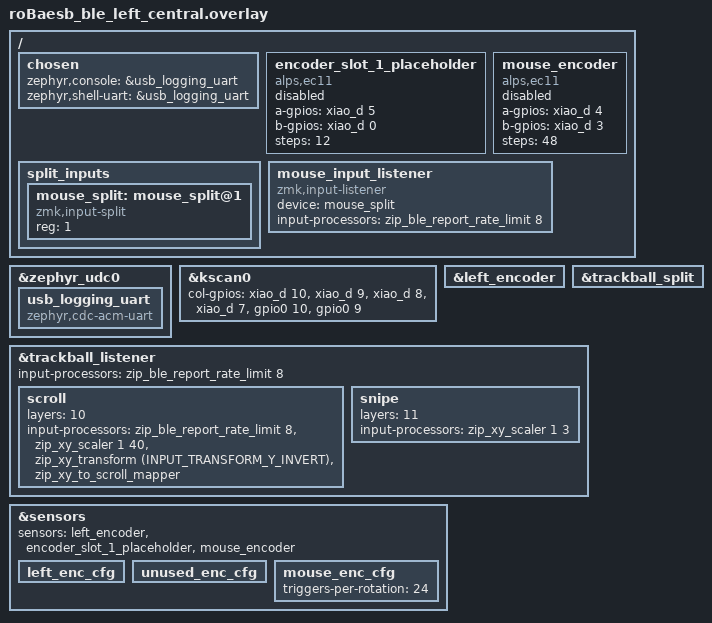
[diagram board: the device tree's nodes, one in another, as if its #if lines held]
/*
 * Left half of roBa acting as ESB central + BLE host.
 *
 * Peripherals:
 *   roBaesb_right  (ID=2, reg=0) — right keys + PMW3610 trackball
 *   lariska_esb    (ID=3, reg=1) — PAW3395 mouse + 5 buttons
 *
 * Both peripherals must use roBaesb_addr.dtsi (the standard address set).
 */

#include "../roBa/roBa.dtsi"
#ifdef ZMK_ESB_ADDR_B
#include "roBaesb_addr_b.dtsi"
#else
#include "roBaesb_addr.dtsi"
#endif
#ifdef ZMK_ESB_MOUSE
#include "roBaesb_lariska_transform.dtsi"
#endif

#include <input/processors/xyz.dtsi>
#include <input/processors/report_rate_limit.dtsi>

/ {
    chosen {
        zephyr,console = &usb_logging_uart;
        zephyr,shell-uart = &usb_logging_uart;
    };

#ifdef ZMK_ESB_MOUSE
    /* Disabled EC11 at sensors[2] - positional placeholder so lariska's encoder
     * (which fires at peripheral sensor index 2) maps to sensor-bindings[2].
     * encoder_slot_1_placeholder at [1] keeps that index stable without
     * implying there is a physical right-side encoder on this build. */
    encoder_slot_1_placeholder: encoder_slot_1_placeholder {
        compatible = "alps,ec11";
        a-gpios = <&xiao_d 5 (GPIO_ACTIVE_HIGH | GPIO_PULL_UP)>;
        b-gpios = <&xiao_d 0 (GPIO_ACTIVE_HIGH | GPIO_PULL_UP)>;
        steps = <12>;
        status = "disabled";
    };

    mouse_encoder: mouse_encoder {
        compatible = "alps,ec11";
        a-gpios = <&xiao_d 4 (GPIO_ACTIVE_HIGH | GPIO_PULL_UP)>;
        b-gpios = <&xiao_d 3 (GPIO_ACTIVE_HIGH | GPIO_PULL_UP)>;
        steps = <48>;
        status = "disabled";
    };

    split_inputs {
        mouse_split: mouse_split@1 {
            compatible = "zmk,input-split";
            reg = <1>;
            status = "okay";
        };
    };

    mouse_input_listener: mouse_input_listener {
        compatible = "zmk,input-listener";
        status = "okay";
        device = <&mouse_split>;
        input-processors = <&zip_ble_report_rate_limit 8>;
    };
#endif
};

&zephyr_udc0 {
    usb_logging_uart: usb_logging_uart {
        compatible = "zephyr,cdc-acm-uart";
    };
};

/* Left-half column wiring (6 cols, col-offset stays at default 0) */
&kscan0 {
    col-gpios
        = <&xiao_d 10 GPIO_ACTIVE_HIGH>
        , <&xiao_d 9 GPIO_ACTIVE_HIGH>
        , <&xiao_d 8 GPIO_ACTIVE_HIGH>
        , <&xiao_d 7 GPIO_ACTIVE_HIGH>
        , <&gpio0 10 GPIO_ACTIVE_HIGH>
        , <&gpio0 9 GPIO_ACTIVE_HIGH>
        ;
};

&left_encoder {
    status = "okay";
};

/* Receive PMW3610 events from roBaesb_right peripheral (reg=0).
 * Sigmoid accel is computed on the right side before ESB send. */
&trackball_split {
    status = "okay";
};

&trackball_listener {
    status = "okay";
    input-processors = <&zip_ble_report_rate_limit 8>;

    scroll {
        layers = <10>;
        input-processors = <&zip_ble_report_rate_limit 8>, <&zip_xy_scaler 1 40>, <&zip_xy_transform (INPUT_TRANSFORM_Y_INVERT)>, <&zip_xy_to_scroll_mapper>;
    };

    snipe {
        layers = <11>;
        input-processors =  <&zip_xy_scaler 1 3>;
    };
};

#ifdef ZMK_ESB_MOUSE
&sensors {
    sensors = <&left_encoder &encoder_slot_1_placeholder &mouse_encoder>;
    left_enc_cfg: left_enc_cfg {};
    unused_enc_cfg: unused_enc_cfg {};
    mouse_enc_cfg: mouse_enc_cfg {
        triggers-per-rotation = <24>;
    };
};
#endif
